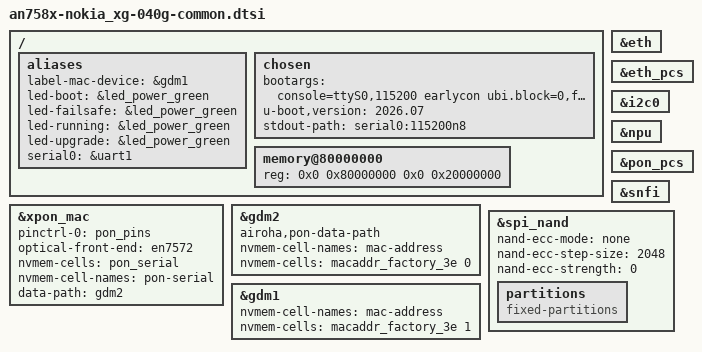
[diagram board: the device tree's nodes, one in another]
// SPDX-License-Identifier: GPL-2.0-only OR MIT

/ {
	aliases {
		label-mac-device = &gdm1;

		led-boot = &led_power_green;
		led-failsafe = &led_power_green;
		led-running = &led_power_green;
		led-upgrade = &led_power_green;

		serial0 = &uart1;
	};

	chosen {
		/*
		 * root= 必须给出：fitblk/ubi block 会把 fit 卷映射成 /dev/fit0。
		 * 与上游同系列板（an7581-q1000k.dts / an7581-w1700k-ubi.dts）逐字一致。
		 * 缺这条会停在 VFS: Cannot open root device "(null)"。
		 */
		bootargs = "console=ttyS0,115200 earlycon ubi.block=0,fit root=/dev/fit0 rootwait";
		/*
		 * fitblk 驱动在 init 里检查 /chosen 是否有 u-boot,version；
		 * 没有就直接 return 0、不注册 /dev/fit0（实测卡在
		 * "Waiting for root device /dev/fit0..."）。u-boot 正常会用
		 * fdt_setprop 写入该属性，这里给出同值兜底。
		 */
		u-boot,version = "2026.07";
		stdout-path = "serial0:115200n8";
	};

	memory@80000000 {
		device_type = "memory";
		reg = <0x0 0x80000000 0x0 0x20000000>;
	};
};

&eth {
	status = "okay";
};

&eth_pcs {
	status = "okay";
};

&i2c0 {
	status = "okay";
};

&npu {
	/*
	 * NPU/PPE（硬件转发引擎）需要开启：LAN 走 DSA 时它不参与，
	 * 而 PON 的 GEM 转发与 offload 元数据依赖它（见 patches-5.4/925）。
	 * 早前为排查标签路径临时关过，已排除 —— 真正的标签问题在 DSA
	 * 的 hw-port-mux 元数据（补丁 126），与 NPU 无关。
	 */
	status = "okay";
};

&pon_pcs {
	status = "okay";
};

&xpon_mac {
	pinctrl-names = "default";
	pinctrl-0 = <&pon_pins>;
	optical-front-end = <&en7572>;
	nvmem-cells = <&pon_serial>;
	nvmem-cell-names = "pon-serial";
	/* data-path references the GDM carrying service GEM traffic. */
	data-path = <&gdm2>;
	status = "okay";
};

&gdm2 {
	/* GDM2 carries the PON GEM data plane on AN7581 and AN7583. */
	airoha,pon-data-path;
	/* WAN uses the eth0 MAC stored at RI offset 0x3e. */
	nvmem-cell-names = "mac-address";
	nvmem-cells = <&macaddr_factory_3e 0>;
	status = "okay";
};

&snfi {
	status = "okay";
};

&spi_nand {
	/*
	 * Bootloader stores pages without host ECC, so Linux uses
	 * NAND_ECC_NONE for the same page layout.
	 */
	nand-ecc-mode = "none";
	nand-ecc-step-size = <2048>;
	nand-ecc-strength = <0>;

	partitions: partitions {
		compatible = "fixed-partitions";
		#address-cells = <1>;
		#size-cells = <1>;
	};
};

&gdm1 {
	status = "okay";

	nvmem-cell-names = "mac-address";
	nvmem-cells = <&macaddr_factory_3e 1>;
};
